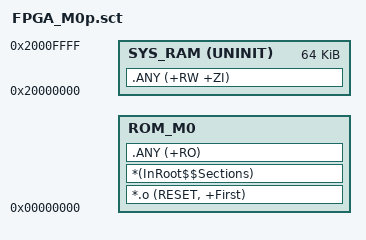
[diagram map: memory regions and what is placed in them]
; *************************************************************
; *** Scatter-Loading Description File generated by uVision ***
; *************************************************************

SOC 0x00000000 0x00020000       ; load region size_region
{
    ROM_M0 0x00000000           ; load address = execution address
    {
        *.o (RESET, +First)
        *(InRoot$$Sections)
        .ANY (+RO)
    }

    ;ROM_M4 0x00000400 FIXED
    ;{
    ;    startup_armcm0plus.o (M4BIN)
    ;}

    SYS_RAM 0x20000000 UNINIT 0x00010000        ; RW data
    {
        .ANY (+RW +ZI)
    }

    ;RET_RAM 0x20010000 UNINIT 0x00002000
    ;{
    ;    .ANY (+RW +ZI)
    ;}
}

